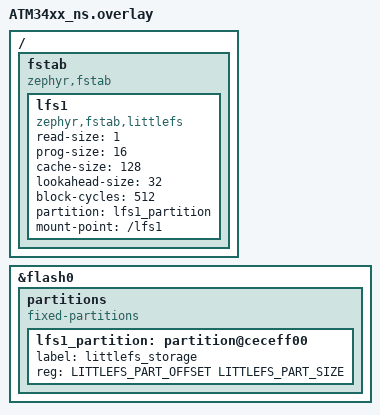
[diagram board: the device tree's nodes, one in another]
/*
 * Copyright (c) 2025 Atmosic
 *
 * SPDX-License-Identifier: Apache-2.0
 */

/ {
    fstab {
        compatible = "zephyr,fstab";
        lfs1: lfs1 {
            compatible = "zephyr,fstab,littlefs";
            read-size = <1>;
            prog-size = <16>;
            cache-size = <128>;
            lookahead-size = <32>;
            block-cycles = <512>;
            partition = <&lfs1_partition>;
            mount-point = "/lfs1";
        };
    };
};

#define LITTLEFS_PART_SIZE 0x3000
// Make sure there is no overlap with prior partitions.
#define LITTLEFS_PART_OFFSET (FLASH_SIZE - LITTLEFS_PART_SIZE)

&flash0 {
        partitions {
                compatible = "fixed-partitions";
                #address-cells = <1>;
                #size-cells = <1>;
                lfs1_partition: partition@ceceff00 {
                        label = "littlefs_storage";
                        reg = <LITTLEFS_PART_OFFSET LITTLEFS_PART_SIZE>;
                };
        };
};
